# STM32H7B0xxQ register map
File version: 1.0
Registers are 32-bit, read-write, reset 0x0 unless marked. A register's access mark holds for its fields unless they carry their own. Offsets are from the block's base; [hi:lo] are bit positions; {n}, {i} and the like mark numbered series.

## HASH
Base 0x48021400
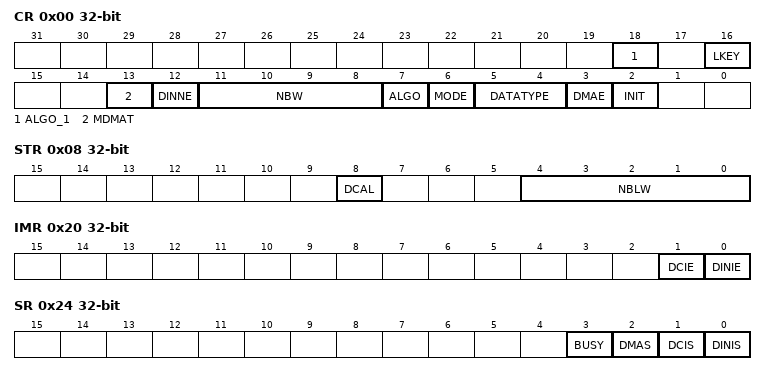
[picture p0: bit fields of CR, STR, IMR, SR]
0x00 CR — HASH control register
  [18] ALGO_1, [16] LKEY, [13] MDMAT, [12] DINNE, [11:8] NBW, [7] ALGO, [6] MODE, [5:4] DATATYPE, [3] DMAE, [2] INIT
0x04 DIN — HASH data input register
0x08 STR — HASH start register
  [8] DCAL, [4:0] NBLW
{0xC+4i} HR{i} (i=0..4) — HASH digest registers
0x20 IMR — HASH interrupt enable register
  [1] DCIE, [0] DINIE
0x24 SR — HASH status register
  [3] BUSY, [2] DMAS, [1] DCIS, [0] DINIS
{0xF8+4i} CSR{i} (i=0..53) — HASH context swap registers
{0x310+4i} DIGEST_HR{i} (i=0..7) — HASH digest registers

## RNG
Base 0x48021800
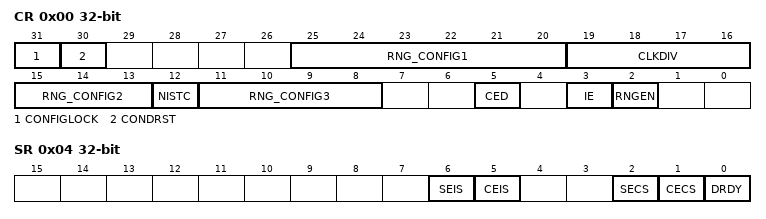
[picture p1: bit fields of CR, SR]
0x00 CR — RNG control register
  [31] CONFIGLOCK
  [30] CONDRST
  [25:20] RNG_CONFIG1
  [19:16] CLKDIV
    0=BY_1 (No clock division); 1=BY_2 (2 RNG clock cycles per internal RNG clock); 2=BY_4 (4 RNG clock cycles per internal RNG clock); 3=BY_8 (8 RNG clock cycles per internal RNG clock); 4=BY_16 (16 RNG clock cycles per internal RNG clock); 5=BY_32 (32 RNG clock cycles per internal RNG clock); 6=BY_64 (64 RNG clock cycles per internal RNG clock); 7=BY_128 (128 RNG clock cycles per internal RNG clock); 8=BY_256 (256 RNG clock cycles per internal RNG clock); 9=BY_512 (512 RNG clock cycles per internal RNG clock); 10=BY_1024 (1024 RNG clock cycles per internal RNG clock); 11=BY_2048 (2048 RNG clock cycles per internal RNG clock); 12=BY_4096 (4096 RNG clock cycles per internal RNG clock); 13=BY_8192 (8192 RNG clock cycles per internal RNG clock); 14=BY_16384 (16384 RNG clock cycles per internal RNG clock); 15=BY_32768 (32768 RNG clock cycles per internal RNG clock)
  [15:13] RNG_CONFIG2
  [12] NISTC
  [11:8] RNG_CONFIG3
  [5] CED
  [3] IE
  [2] RNGEN
0x04 SR — RNG status register
  [6] SEIS, [5] CEIS, [2] SECS, [1] CECS, [0] DRDY
0x08 DR — RNG data register
0x10 HTCR — RNG health test configuration register

## DLYB_SDMMC2 — Delay Block DLYB
Base 0x48022800
Same registers: DLYB_OCTOSPI1 0x52006000, DLYB_SDMMC1 0x52008000, DLYB_OCTOSPI2 0x5200B000
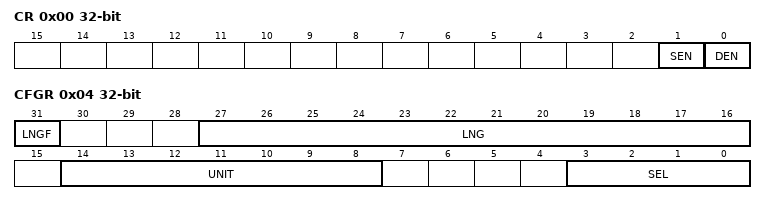
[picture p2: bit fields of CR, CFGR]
0x00 CR — DELAY BLOCK control register
  [1] SEN — Sampler length enable
  [0] DEN — Delay Block enable
0x04 CFGR — DELAY BLOCK configuration register
  [31] LNGF — Length valid flag
  [27:16] LNG — Delay line length value[11:0]
  [14:8] UNIT — Delay Defines the delay of a Unit delay cell[6:0]
  [3:0] SEL — Select the phase for the Output clock[3:0]

## BDMA1
Base 0x48022C00
Same registers: BDMA2 0x58025400
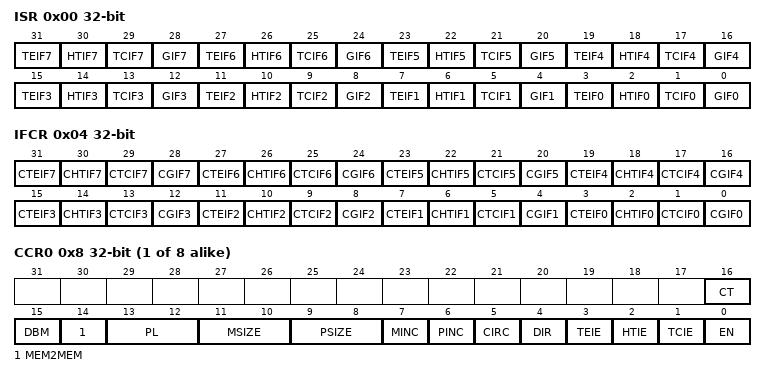
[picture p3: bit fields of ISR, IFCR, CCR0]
0x00 ISR — DMA interrupt status register
  [4n+3] TEIF{n} (n=0..7) — Channel {n} Transfer Error flag
  [4n+2] HTIF{n} (n=0..7) — Channel {n} Half Transfer flag
  [4n+1] TCIF{n} (n=0..7) — Channel {n} Transfer Complete flag
  [4n] GIF{n} (n=0..7) — Channel {n} Global interrupt flag
0x04 IFCR — DMA interrupt flag clear register
  [4n+3] CTEIF{n} (n=0..7) — Channel {n} Transfer Error clear
  [4n+2] CHTIF{n} (n=0..7) — Channel {n} Half Transfer clear
  [4n+1] CTCIF{n} (n=0..7) — Channel {n} Transfer Complete clear
  [4n] CGIF{n} (n=1..7) — Channel {n} Global interrupt clear
  [0] CGIF0 — Channel 0 Global interrupt clearr
{0x8+0x14*i} CCR{i} (i=0..7) — DMA channel x configuration register
  [16] CT — Memory to memory mode
  [15] DBM — Memory to memory mode
  [14] MEM2MEM — Memory to memory mode
  [13:12] PL — PL[1:0] bits(Channel Priority level)
  [11:10] MSIZE — MSIZE[1:0] bits (Memory size)
  [9:8] PSIZE — PSIZE[1:0] bits (Peripheral size)
  [7] MINC — Memory increment mode
  [6] PINC — Peripheral increment mode
  [5] CIRC — Circular mode
  [4] DIR — Data transfer direction
  [3] TEIE — Transfer error interrupt enable
  [2] HTIE — Half Transfer interrupt enable
  [1] TCIE — Transfer complete interrupt enable
  [0] EN — Channel enable
{0xC+0x14*i} CNDTR{i} (i=0..7) — DMA channel x number of data register
  [15:0] NDT — Number of data to Transfer
{0x10+0x14*i} CPAR{i} (i=0..7) — DMA channel x peripheral address register
  [31:0] PA — Peripheral Address
{0x14+0x14*i} CM0AR{i} (i=0..7) — DMA channel x memory 0 address register
  [31:0] MA — Memory Address
{0x18+0x14*i} CM1AR{i} (i=0..7) — DMA channel x memory 1 address register
  [31:0] MA — Memory Address
